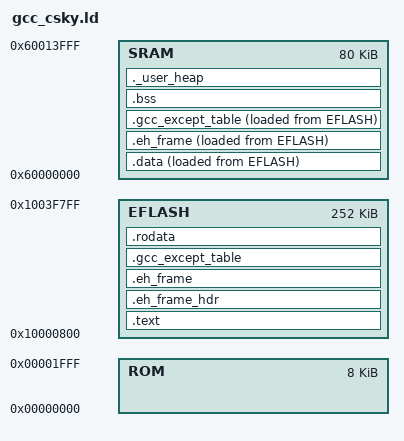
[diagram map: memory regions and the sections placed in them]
/*
 * Copyright (C) 2017 C-SKY Microsystems Co., Ltd. All rights reserved.
 *
 * Licensed under the Apache License, Version 2.0 (the "License");
 * you may not use this file except in compliance with the License.
 * You may obtain a copy of the License at
 *
 *   http://www.apache.org/licenses/LICENSE-2.0
 *
 * Unless required by applicable law or agreed to in writing, software
 * distributed under the License is distributed on an "AS IS" BASIS,
 * WITHOUT WARRANTIES OR CONDITIONS OF ANY KIND, either express or implied.
 * See the License for the specific language governing permissions and
 * limitations under the License.
 */

/******************************************************************************
 * @file     gcc_csky.ld
 * @brief    csky linker file
 * @version  V1.0
 * @date     02. June 2017
 ******************************************************************************/
MEMORY
{
    ROM    : ORIGIN = 0x0        , LENGTH = 0x2000    /* ROM  8KB*/
    EFLASH : ORIGIN = 0x10000800 , LENGTH = 0x3f000   /* E-FLASH 252KB*/
    SRAM   : ORIGIN = 0x60000000 , LENGTH = 0x14000   /* on-chip SRAM 80KB*/
}

__min_heap_size = 0x200;
PROVIDE (__ram_end  = 0x60014000);
PROVIDE (__heap_end = __ram_end);

REGION_ALIAS("REGION_TEXT",    EFLASH);
REGION_ALIAS("REGION_RODATA",  EFLASH);
REGION_ALIAS("REGION_DATA",    SRAM);
REGION_ALIAS("REGION_BSS",     SRAM);

ENTRY(Reset_Handler)
SECTIONS
{
 .text : {
  . = ALIGN(0x4) ;
  *startup.o(*.text)
  __stext = . ;
  *(.text)
  *(.text*)
  *(.text.*)
  *(.gnu.warning)
  *(.stub)
  *(.gnu.linkonce.t*)
  *(.glue_7t)
  *(.glue_7)
  *(.jcr)
  KEEP (*(.init))
  KEEP (*(.fini))
  . = ALIGN (4) ;
  PROVIDE(__ctbp = .);
  *(.call_table_data)
  *(.call_table_text)
  . = ALIGN(0x10) ;
  __etext = . ;
 } > REGION_TEXT
 .eh_frame_hdr : {
  *(.eh_frame_hdr)
 } > REGION_TEXT
 .eh_frame : ONLY_IF_RO {
  KEEP (*(.eh_frame))
 } > REGION_TEXT
 .gcc_except_table : ONLY_IF_RO {
  *(.gcc_except_table .gcc_except_table.*)
 } > REGION_TEXT
 .rodata : {
  . = ALIGN(0x4) ;
  __srodata = .;
  *(.rdata)
  *(.rdata*)
  *(.rdata1)
  *(.rdata.*)
  *(.rodata)
  *(.rodata1)
  *(.rodata*)
  *(.rodata.*)
  *(.rodata.str1.4)
  KEEP (*crtbegin.o(.ctors))
  KEEP (*crtbegin?.o(.ctors))
  KEEP (*(EXCLUDE_FILE (*crtend.o *crtend?.o ) .ctors))
  KEEP (*(SORT(.ctors.*)))
  KEEP (*(.ctors))
  KEEP (*crtbegin.o(.dtors))
  KEEP (*crtbegin?.o(.dtors))
  KEEP (*(EXCLUDE_FILE (*crtend.o *crtend?.o ) .dtors))
  KEEP (*(SORT(.dtors.*)))
  KEEP (*(.dtors))
  . = ALIGN(0x4) ;
  __erodata = .;
  __rodata_end__ = .;
 } > REGION_RODATA
 .data : {
  . = ALIGN(0x4) ;
  __sdata = . ;
  __data_start__ = . ;
  data_start = . ;
  KEEP(*startup.o(.vectors))
  *(.got.plt)
  *(.got)
  *(.gnu.linkonce.r*)
  *(.data)
  *(.data*)
  *(.data1)
  *(.data.*)
  *(.gnu.linkonce.d*)
  *(.data1)
  *(.gcc_except_table)
  *(.gcc_except_table*)
  __start_init_call = .;
  *(.initcall.init)
  __stop_init_call = .;
  __start_cmd = .;
  *(.bootloaddata.cmd)
  . = ALIGN(4) ;
  __stop_cmd = .;
  *(.sdata)
  *(.sdata.*)
  *(.gnu.linkonce.s.*)
  *(__libc_atexit)
  *(__libc_subinit)
  *(__libc_subfreeres)
  *(.note.ABI-tag)
  __edata = .;
  __data_end__ = .;
  . = ALIGN(0x4) ;
 } > REGION_DATA AT > REGION_RODATA
 .eh_frame : ONLY_IF_RW {
  KEEP (*(.eh_frame))
 } > REGION_DATA AT > REGION_RODATA
 .gcc_except_table : ONLY_IF_RW {
  *(.gcc_except_table .gcc_except_table.*)
  __edata = .;
  __data_end__ = .;
 } > REGION_DATA AT > REGION_RODATA
 .bss : {
  . = ALIGN(0x4) ;
  __sbss = ALIGN(0x4) ;
  __bss_start__ = . ;
  *(.dynsbss)
  *(.sbss)
  *(.sbss.*)
  *(.scommon)
  *(.dynbss)
  *(.bss)
  *(.bss.*)
  *(COMMON)
  . = ALIGN(0x4) ;
  __ebss = . ;
  __bss_end__ = .;
  __end = . ;
  end = . ;
 } > REGION_BSS AT > REGION_BSS
 ._user_heap : {
  . = ALIGN(0x4) ;
  __heap_start = .;
  . += __min_heap_size;
  . = ALIGN(0x4) ;
 } > REGION_BSS AT > REGION_BSS
}
